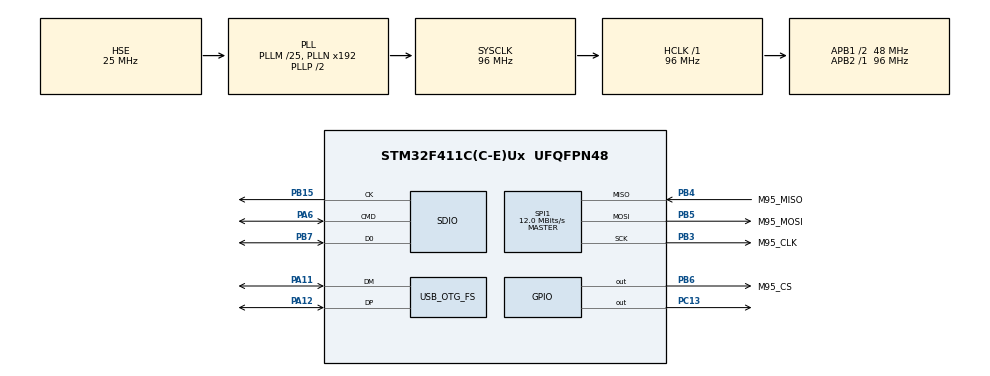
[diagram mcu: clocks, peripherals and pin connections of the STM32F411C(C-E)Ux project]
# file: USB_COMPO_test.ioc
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AL94.I-CUBE-USBD-COMPOSITE.1.0.3.CompositeCcUSBJjCOMPOSITEJjCDCIiACM=true
AL94.I-CUBE-USBD-COMPOSITE.1.0.3.CompositeCcUSBJjCOMPOSITEJjCOMPOSITE=true
AL94.I-CUBE-USBD-COMPOSITE.1.0.3.CompositeCcUSBJjCOMPOSITEJjCore=true
AL94.I-CUBE-USBD-COMPOSITE.1.0.3.CompositeCcUSBJjCOMPOSITEJjMSCIiBOT=true
AL94.I-CUBE-USBD-COMPOSITE.1.0.3._USBD_USE_CDC_ACM=true
AL94.I-CUBE-USBD-COMPOSITE.1.0.3._USBD_USE_HS=false
AL94.I-CUBE-USBD-COMPOSITE.1.0.3._USBD_USE_MSC=true
Mcu.Family=STM32F4
Mcu.Name=STM32F411C(C-E)Ux
Mcu.Package=UFQFPN48
NVIC.OTG_FS_IRQn=true\:14\:0\:true\:false\:true\:true\:true\:true
NVIC.PriorityGroup=NVIC_PRIORITYGROUP_4
NVIC.SDIO_IRQn=true\:0\:0\:false\:false\:true\:true\:true\:true
PA11.Mode=Device_Only
PA11.Signal=USB_OTG_FS_DM
PA12.Mode=Device_Only
PA12.Signal=USB_OTG_FS_DP
PA6.Mode=SD_1_bit
PA6.Signal=SDIO_CMD
PB15.Mode=SD_1_bit
PB15.Signal=SDIO_CK
PB3.GPIO_Label=M95_CLK
PB3.Mode=Full_Duplex_Master
PB3.Signal=SPI1_SCK
PB4.GPIO_Label=M95_MISO
PB4.Mode=Full_Duplex_Master
PB4.Signal=SPI1_MISO
PB5.GPIO_Label=M95_MOSI
PB5.Mode=Full_Duplex_Master
PB5.Signal=SPI1_MOSI
PB6.GPIO_Label=M95_CS
PB6.Signal=GPIO_Output
PB7.Mode=SD_1_bit
PB7.Signal=SDIO_D0
PC13-ANTI_TAMP.Signal=GPIO_Output
PH0\ -\ OSC_IN.Mode=HSE-External-Oscillator
PH0\ -\ OSC_IN.Signal=RCC_OSC_IN
PH1\ -\ OSC_OUT.Mode=HSE-External-Oscillator
PH1\ -\ OSC_OUT.Signal=RCC_OSC_OUT
ProjectManager.HeapSize=0x600
ProjectManager.StackSize=0x800
ProjectManager.TargetToolchain=STM32CubeIDE
RCC.48MHZClocksFreq_Value=48000000
RCC.AHBFreq_Value=96000000
RCC.APB1CLKDivider=RCC_HCLK_DIV2
RCC.APB1Freq_Value=48000000
RCC.APB1TimFreq_Value=96000000
RCC.APB2Freq_Value=96000000
RCC.APB2TimFreq_Value=96000000
RCC.CortexFreq_Value=96000000
RCC.HCLKFreq_Value=96000000
RCC.HSE_VALUE=25000000
RCC.HSI_VALUE=16000000
RCC.LSE_VALUE=32768
RCC.PLLM=25
RCC.SYSCLKFreq_VALUE=96000000
RCC.SYSCLKSource=RCC_SYSCLKSOURCE_PLLCLK
RCC.VCOOutputFreq_Value=192000000
SDIO.ClockDiv=8-1
SPI1.BaudRatePrescaler=SPI_BAUDRATEPRESCALER_8
SPI1.CalculateBaudRate=12.0 MBits/s
SPI1.Direction=SPI_DIRECTION_2LINES
SPI1.Mode=SPI_MODE_MASTER
SPI1.VirtualType=VM_MASTER
USB_OTG_FS.VirtualMode=Device_Only
VP_AL94.I-CUBE-USBD-COMPOSITE_VS_USBJjComposite_1.0.0_1.0.3.Mode=USBJjComposite
board=custom

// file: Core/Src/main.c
/* USER CODE BEGIN Header */
/**
  ******************************************************************************
  * @file           : main.c
  * @brief          : Main program body
  ******************************************************************************
  * @attention
  *
  * Copyright (c) 2026 STMicroelectronics.
  * All rights reserved.
  *
  * This software is licensed under terms that can be found in the LICENSE file
  * in the root directory of this software component.
  * If no LICENSE file comes with this software, it is provided AS-IS.
  *
  ******************************************************************************
  */
/* USER CODE END Header */
#include "main.h"
#include "sdio.h"
#include "spi.h"
#include "usb_otg.h"
#include "gpio.h"

/* USER CODE BEGIN Includes */

#include "App_main.h"
#include "usb_device.h"

/* USER CODE END Includes */

void SystemClock_Config(void);

int main(void)
{

  /* MCU Configuration--------------------------------------------------------*/

  /* Reset of all peripherals, Initializes the Flash interface and the Systick. */
  HAL_Init();

  /* Configure the system clock */
  SystemClock_Config();

  /* Initialize all configured peripherals */
  MX_GPIO_Init();
  MX_SPI1_Init();
  MX_SDIO_SD_Init();
  MX_USB_OTG_FS_PCD_Init();
  /* USER CODE BEGIN 2 */

  MX_USB_DEVICE_Init();

  /* USER CODE END 2 */

  /* Infinite loop */
  /* USER CODE BEGIN WHILE */
  while (1)
  {
	  app_main();
    /* USER CODE END WHILE */

  }
}

void SystemClock_Config(void)
{
  RCC_OscInitTypeDef RCC_OscInitStruct = {0};
  RCC_ClkInitTypeDef RCC_ClkInitStruct = {0};

  /** Configure the main internal regulator output voltage
  */
  __HAL_RCC_PWR_CLK_ENABLE();
  __HAL_PWR_VOLTAGESCALING_CONFIG(PWR_REGULATOR_VOLTAGE_SCALE1);

  /** Initializes the RCC Oscillators according to the specified parameters
  * in the RCC_OscInitTypeDef structure.
  */
  RCC_OscInitStruct.OscillatorType = RCC_OSCILLATORTYPE_HSE;
  RCC_OscInitStruct.HSEState = RCC_HSE_ON;
  RCC_OscInitStruct.PLL.PLLState = RCC_PLL_ON;
  RCC_OscInitStruct.PLL.PLLSource = RCC_PLLSOURCE_HSE;
  RCC_OscInitStruct.PLL.PLLM = 25;
  RCC_OscInitStruct.PLL.PLLN = 192;
  RCC_OscInitStruct.PLL.PLLP = RCC_PLLP_DIV2;
  RCC_OscInitStruct.PLL.PLLQ = 4;
  if (HAL_RCC_OscConfig(&RCC_OscInitStruct) != HAL_OK)
  {
    Error_Handler();
  }

  /** Initializes the CPU, AHB and APB buses clocks
  */
  RCC_ClkInitStruct.ClockType = RCC_CLOCKTYPE_HCLK|RCC_CLOCKTYPE_SYSCLK
                              |RCC_CLOCKTYPE_PCLK1|RCC_CLOCKTYPE_PCLK2;
  RCC_ClkInitStruct.SYSCLKSource = RCC_SYSCLKSOURCE_PLLCLK;
  RCC_ClkInitStruct.AHBCLKDivider = RCC_SYSCLK_DIV1;
  RCC_ClkInitStruct.APB1CLKDivider = RCC_HCLK_DIV2;
  RCC_ClkInitStruct.APB2CLKDivider = RCC_HCLK_DIV1;

  if (HAL_RCC_ClockConfig(&RCC_ClkInitStruct, FLASH_LATENCY_3) != HAL_OK)
  {
    Error_Handler();
  }
}

void Error_Handler(void)
{
  __disable_irq();
  while (1)
  {
  }
}
